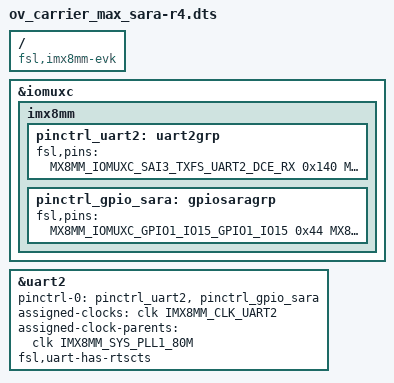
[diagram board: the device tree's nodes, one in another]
/**
 * Portenta-X8 dtb overlay file
 * Arduino 2021
 * Enable SARA-R4 modem serial port on Arduino Max carrier board.
 * No audio signals are connected to the modem.
 * In order for the modem to work ov_carrier_enuc_usbfs overlay need to be included.
 * Gpios:
 * - Reset pin active low
 * - Power on pin active high
 */

/dts-v1/;
/plugin/;

#include "imx8mm-pinfunc.h"
#include <dt-bindings/clock/imx8mm-clock.h>

/* @TODO they shall be introduced in recent bsps from nxp */
/* NOTE: DCE mode not inverted */
#define MX8MM_IOMUXC_SAI3_TXFS_UART2_DCE_RX     0x1D8 0x440 0x4Fc 0x4 0x2
#define MX8MM_IOMUXC_SAI3_TXC_UART2_DCE_TX      0x1DC 0x444 0x000 0x4 0x0
#define MX8MM_IOMUXC_SAI3_RXC_UART2_DCE_CTS_B   0x1D0 0x438 0x000 0x4 0x0
#define MX8MM_IOMUXC_SAI3_RXD_UART2_DCE_RTS_B   0x1D4 0x43C 0x4F8 0x4 0x3

/ {
	compatible = "fsl,imx8mm-evk", "fsl,imx8mm";

	fragment@0 {
		target = <&iomuxc>;
		__overlay__ {
			imx8mm {
				pinctrl_uart2: uart2grp {
					fsl,pins = <
						MX8MM_IOMUXC_SAI3_TXFS_UART2_DCE_RX			0x140
						MX8MM_IOMUXC_SAI3_TXC_UART2_DCE_TX			0x140
						MX8MM_IOMUXC_SAI3_RXC_UART2_DCE_CTS_B		0x140
						MX8MM_IOMUXC_SAI3_RXD_UART2_DCE_RTS_B		0x140
					>;
				};

				/* @TODO: fix me Sara-R4 modem reset and power on pass thru stm32h7 */
				pinctrl_gpio_sara: gpiosaragrp {
					fsl,pins = <
						MX8MM_IOMUXC_GPIO1_IO15_GPIO1_IO15			0x44 /* RST active low stm32h7 PF3 */
						MX8MM_IOMUXC_SAI1_MCLK_GPIO4_IO20			0x44 /* POWER_ON active high stm32h7 PF12 */
					>;
				};
			};
		};
	};

	fragment@1 {
		target = <&uart2>;
		__overlay__ {
			pinctrl-names = "default";
			pinctrl-0 = <&pinctrl_uart2>, <&pinctrl_gpio_sara>;
			assigned-clocks = <&clk IMX8MM_CLK_UART2>;
			assigned-clock-parents = <&clk IMX8MM_SYS_PLL1_80M>;
			fsl,uart-has-rtscts;
			status = "okay";
		};
	};
};
